# 32-kHz_synchronized_timer register map
Vendor: Texas Instruments
Peripheral module from a debugger description file (folder omap4430).
Registers are 32-bit, read-only, no defined reset value unless marked. A register's access mark holds for its fields unless they carry their own. Offsets are as the file gives them; lines under a group give offsets from that group; [hi:lo] are bit positions; {n}, {i} and the like mark numbered series; 'fields as' and 'values as' point back to an identical list; <NAME> marks a mode.

## 32KTimer
0x00 _32KSYNCNT_REV — This register contains the sync counter IP revision code.
  [31:0] REVISION — IP Revision
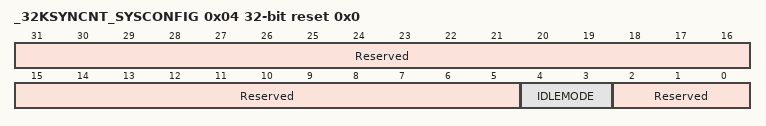
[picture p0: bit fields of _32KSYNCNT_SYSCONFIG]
0x04 _32KSYNCNT_SYSCONFIG access per field reset 0x0 — This register is used for IDLE modes only.
  [31:5] Reserved ro — Reads return 0.
  [4:3] IDLEMODE rw — Power management REQ/ACK control
  [2:0] Reserved ro — Reads return 0.
0x10 _32KSYNCNT_CR reset 0x3 — This register contains the 32-kHz sync counter value.
  [31:0] COUNTER_VALUE — Counter register value
